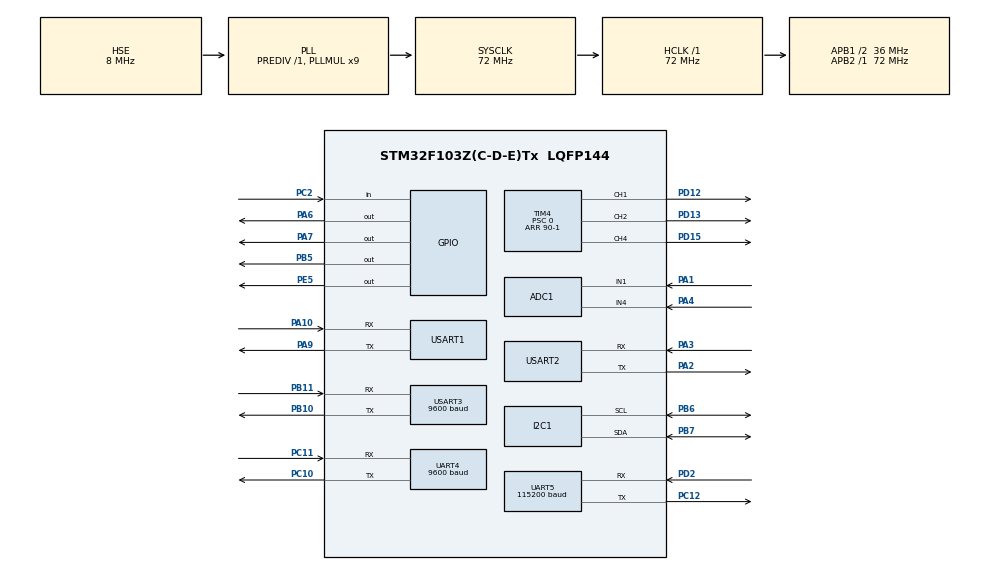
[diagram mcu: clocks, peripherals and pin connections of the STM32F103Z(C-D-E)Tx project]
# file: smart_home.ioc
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ADC1.Channel-0\#ChannelRegularConversion=ADC_CHANNEL_1
ADC1.Channel-1\#ChannelRegularConversion=ADC_CHANNEL_4
ADC1.ContinuousConvMode=ENABLE
ADC1.NbrOfConversion=2
ADC1.NbrOfConversionFlag=1
ADC1.Rank-0\#ChannelRegularConversion=1
ADC1.Rank-1\#ChannelRegularConversion=2
ADC1.SamplingTime-0\#ChannelRegularConversion=ADC_SAMPLETIME_239CYCLES_5
ADC1.SamplingTime-1\#ChannelRegularConversion=ADC_SAMPLETIME_239CYCLES_5
ADC1.master=1
Dma.ADC1.0.Direction=DMA_PERIPH_TO_MEMORY
Dma.ADC1.0.Instance=DMA1_Channel1
Dma.ADC1.0.MemDataAlignment=DMA_MDATAALIGN_HALFWORD
Dma.ADC1.0.MemInc=DMA_MINC_ENABLE
Dma.ADC1.0.Mode=DMA_CIRCULAR
Dma.ADC1.0.PeriphDataAlignment=DMA_PDATAALIGN_HALFWORD
Dma.ADC1.0.PeriphInc=DMA_PINC_DISABLE
Dma.ADC1.0.Priority=DMA_PRIORITY_LOW
Dma.Request0=ADC1
Dma.Request1=TIM4_UP
Dma.Request2=TIM4_CH2
Dma.TIM4_CH2.2.Direction=DMA_MEMORY_TO_PERIPH
Dma.TIM4_CH2.2.Instance=DMA1_Channel4
Dma.TIM4_CH2.2.MemDataAlignment=DMA_MDATAALIGN_HALFWORD
Dma.TIM4_CH2.2.MemInc=DMA_MINC_ENABLE
Dma.TIM4_CH2.2.Mode=DMA_NORMAL
Dma.TIM4_CH2.2.PeriphDataAlignment=DMA_PDATAALIGN_HALFWORD
Dma.TIM4_CH2.2.PeriphInc=DMA_PINC_DISABLE
Dma.TIM4_CH2.2.Priority=DMA_PRIORITY_MEDIUM
Dma.TIM4_UP.1.Direction=DMA_MEMORY_TO_PERIPH
Dma.TIM4_UP.1.Instance=DMA1_Channel7
Dma.TIM4_UP.1.MemDataAlignment=DMA_MDATAALIGN_HALFWORD
Dma.TIM4_UP.1.MemInc=DMA_MINC_ENABLE
Dma.TIM4_UP.1.Mode=DMA_NORMAL
Dma.TIM4_UP.1.PeriphDataAlignment=DMA_PDATAALIGN_HALFWORD
Dma.TIM4_UP.1.PeriphInc=DMA_PINC_DISABLE
Dma.TIM4_UP.1.Priority=DMA_PRIORITY_MEDIUM
Mcu.Family=STM32F1
Mcu.Name=STM32F103Z(C-D-E)Tx
Mcu.Package=LQFP144
NVIC.DMA1_Channel1_IRQn=true\:0\:0\:false\:false\:true\:false\:true\:true
NVIC.DMA1_Channel4_IRQn=true\:0\:0\:false\:false\:true\:false\:true\:true
NVIC.DMA1_Channel7_IRQn=true\:0\:0\:false\:false\:true\:false\:true\:true
NVIC.PriorityGroup=NVIC_PRIORITYGROUP_4
NVIC.UART4_IRQn=true\:0\:0\:false\:false\:true\:true\:true\:true
NVIC.UART5_IRQn=true\:0\:0\:false\:false\:true\:true\:true\:true
NVIC.USART1_IRQn=true\:0\:0\:false\:false\:true\:true\:true\:true
NVIC.USART2_IRQn=true\:0\:0\:false\:false\:true\:true\:true\:true
NVIC.USART3_IRQn=true\:0\:0\:false\:false\:true\:true\:true\:true
OSC_IN.Mode=HSE-External-Oscillator
OSC_IN.Signal=RCC_OSC_IN
OSC_OUT.Mode=HSE-External-Oscillator
OSC_OUT.Signal=RCC_OSC_OUT
PA1.Signal=ADCx_IN1
PA10.Mode=Asynchronous
PA10.Signal=USART1_RX
PA13.Mode=Serial_Wire
PA13.Signal=SYS_JTMS-SWDIO
PA14.Mode=Serial_Wire
PA14.Signal=SYS_JTCK-SWCLK
PA2.Mode=Asynchronous
PA2.Signal=USART2_TX
PA3.Mode=Asynchronous
PA3.Signal=USART2_RX
PA4.Signal=ADCx_IN4
PA6.Signal=GPIO_Output
PA7.GPIO_ModeDefaultOutputPP=GPIO_MODE_OUTPUT_OD
PA7.GPIO_PuPd=GPIO_PULLUP
PA7.GPIO_Speed=GPIO_SPEED_FREQ_HIGH
PA7.PinState=GPIO_PIN_SET
PA7.Signal=GPIO_Output
PA9.Mode=Asynchronous
PA9.Signal=USART1_TX
PB10.Mode=Asynchronous
PB10.Signal=USART3_TX
PB11.Mode=Asynchronous
PB11.Signal=USART3_RX
PB5.PinState=GPIO_PIN_RESET
PB5.Signal=GPIO_Output
PB6.Mode=I2C
PB6.Signal=I2C1_SCL
PB7.Mode=I2C
PB7.Signal=I2C1_SDA
PC10.Mode=Asynchronous
PC10.Signal=UART4_TX
PC11.Mode=Asynchronous
PC11.Signal=UART4_RX
PC12.Mode=Asynchronous
PC12.Signal=UART5_TX
PC2.GPIO_PuPd=GPIO_PULLUP
PC2.Signal=GPIO_Input
PD12.GPIO_Speed=GPIO_SPEED_FREQ_HIGH
PD12.Signal=S_TIM4_CH1
PD13.GPIO_Speed=GPIO_SPEED_FREQ_HIGH
PD13.Signal=S_TIM4_CH2
PD15.GPIO_Speed=GPIO_SPEED_FREQ_HIGH
PD15.Signal=S_TIM4_CH4
PD2.Mode=Asynchronous
PD2.Signal=UART5_RX
PE5.PinState=GPIO_PIN_SET
PE5.Signal=GPIO_Output
ProjectManager.HeapSize=0x200
ProjectManager.StackSize=0x400
ProjectManager.TargetToolchain=MDK-ARM V5.32
RCC.ADCPresc=RCC_ADCPCLK2_DIV6
RCC.AHBFreq_Value=72000000
RCC.APB1CLKDivider=RCC_HCLK_DIV2
RCC.APB1Freq_Value=36000000
RCC.APB1TimFreq_Value=72000000
RCC.APB2Freq_Value=72000000
RCC.APB2TimFreq_Value=72000000
RCC.HCLKFreq_Value=72000000
RCC.PLLMUL=RCC_PLL_MUL9
RCC.PLLSourceVirtual=RCC_PLLSOURCE_HSE
RCC.SYSCLKFreq_VALUE=72000000
RCC.SYSCLKSource=RCC_SYSCLKSOURCE_PLLCLK
RCC.USBFreq_Value=72000000
SH.ADCx_IN1.0=ADC1_IN1,IN1
SH.ADCx_IN4.0=ADC1_IN4,IN4
SH.S_TIM4_CH1.0=TIM4_CH1,PWM Generation1 CH1
SH.S_TIM4_CH2.0=TIM4_CH2,PWM Generation2 CH2
SH.S_TIM4_CH4.0=TIM4_CH4,PWM Generation4 CH4
TIM4.AutoReloadPreload=TIM_AUTORELOAD_PRELOAD_ENABLE
TIM4.Channel-PWM\ Generation1\ CH1=TIM_CHANNEL_1
TIM4.Channel-PWM\ Generation2\ CH2=TIM_CHANNEL_2
TIM4.Channel-PWM\ Generation4\ CH4=TIM_CHANNEL_4
TIM4.OCMode_PWM-PWM\ Generation1\ CH1=TIM_OCMODE_PWM1
TIM4.OCMode_PWM-PWM\ Generation4\ CH4=TIM_OCMODE_PWM2
TIM4.Period=90-1
TIM4.Prescaler=0
UART4.BaudRate=9600
UART4.VirtualMode=Asynchronous
UART5.BaudRate=115200
UART5.VirtualMode=Asynchronous
USART1.VirtualMode=VM_ASYNC
USART2.VirtualMode=VM_ASYNC
USART3.BaudRate=9600
USART3.VirtualMode=VM_ASYNC
VP_TIM4_VS_ClockSourceINT.Mode=Internal
board=custom

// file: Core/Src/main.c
/* USER CODE BEGIN Header */
/**
  ******************************************************************************
  * @file           : main.c
  * @brief          : Main program body
  ******************************************************************************
  * @attention
  *
  * Copyright (c) 2026 STMicroelectronics.
  * All rights reserved.
  *
  * This software is licensed under terms that can be found in the LICENSE file
  * in the root directory of this software component.
  * If no LICENSE file comes with this software, it is provided AS-IS.
  *
  ******************************************************************************
  */
/* USER CODE END Header */
#include "main.h"
#include "adc.h"
#include "dma.h"
#include "i2c.h"
#include "tim.h"
#include "usart.h"
#include "gpio.h"

/* USER CODE BEGIN Includes */
#include "headfile.h"
#include <stdint.h>
/* USER CODE END Includes */

void SystemClock_Config(void);

int main(void)
{

  /* MCU Configuration--------------------------------------------------------*/

  /* Reset of all peripherals, Initializes the Flash interface and the Systick. */
   HAL_Init();

  /* Configure the system clock */
  SystemClock_Config();

  /* Initialize all configured peripherals */
  MX_GPIO_Init();
  MX_DMA_Init();
  MX_USART1_UART_Init();
  MX_USART2_UART_Init();
  MX_ADC1_Init();
  MX_TIM4_Init();
  MX_I2C1_Init();
  MX_UART4_Init();
  MX_USART3_UART_Init();
  MX_UART5_Init();
  /* USER CODE BEGIN 2 */
	schedule_init();
  /* USER CODE END 2 */

  /* Infinite loop */
  /* USER CODE BEGIN WHILE */
  while (1) {
	 schedule_run();

    /* USER CODE END WHILE */

  }
}

void SystemClock_Config(void)
{
  RCC_OscInitTypeDef RCC_OscInitStruct = {0};
  RCC_ClkInitTypeDef RCC_ClkInitStruct = {0};
  RCC_PeriphCLKInitTypeDef PeriphClkInit = {0};

  /** Initializes the RCC Oscillators according to the specified parameters
  * in the RCC_OscInitTypeDef structure.
  */
  RCC_OscInitStruct.OscillatorType = RCC_OSCILLATORTYPE_HSE;
  RCC_OscInitStruct.HSEState = RCC_HSE_ON;
  RCC_OscInitStruct.HSEPredivValue = RCC_HSE_PREDIV_DIV1;
  RCC_OscInitStruct.HSIState = RCC_HSI_ON;
  RCC_OscInitStruct.PLL.PLLState = RCC_PLL_ON;
  RCC_OscInitStruct.PLL.PLLSource = RCC_PLLSOURCE_HSE;
  RCC_OscInitStruct.PLL.PLLMUL = RCC_PLL_MUL9;
  if (HAL_RCC_OscConfig(&RCC_OscInitStruct) != HAL_OK)
  {
    Error_Handler();
  }

  /** Initializes the CPU, AHB and APB buses clocks
  */
  RCC_ClkInitStruct.ClockType = RCC_CLOCKTYPE_HCLK|RCC_CLOCKTYPE_SYSCLK
                              |RCC_CLOCKTYPE_PCLK1|RCC_CLOCKTYPE_PCLK2;
  RCC_ClkInitStruct.SYSCLKSource = RCC_SYSCLKSOURCE_PLLCLK;
  RCC_ClkInitStruct.AHBCLKDivider = RCC_SYSCLK_DIV1;
  RCC_ClkInitStruct.APB1CLKDivider = RCC_HCLK_DIV2;
  RCC_ClkInitStruct.APB2CLKDivider = RCC_HCLK_DIV1;

  if (HAL_RCC_ClockConfig(&RCC_ClkInitStruct, FLASH_LATENCY_2) != HAL_OK)
  {
    Error_Handler();
  }
  PeriphClkInit.PeriphClockSelection = RCC_PERIPHCLK_ADC;
  PeriphClkInit.AdcClockSelection = RCC_ADCPCLK2_DIV6;
  if (HAL_RCCEx_PeriphCLKConfig(&PeriphClkInit) != HAL_OK)
  {
    Error_Handler();
  }
}

void Error_Handler(void)
{
  __disable_irq();
  while (1)
  {
  }
}
